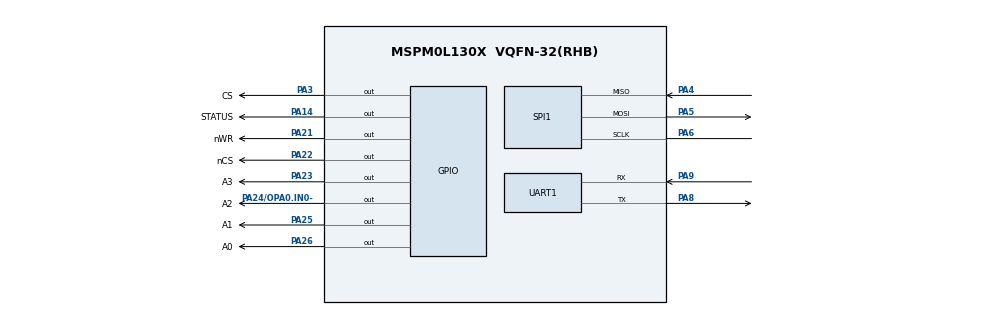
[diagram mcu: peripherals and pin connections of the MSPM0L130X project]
/**
 * @cliArgs --device "MSPM0L130X" --part "Default" --package "VQFN-32(RHB)" --product "mspm0_sdk@2.02.00.05"
 * @versions {"tool":"1.21.0+3721"}
 */

/**
 * Import the modules used in this configuration.
 */
const GPIO          = scripting.addModule("/ti/driverlib/GPIO", {}, false);
const GPIO1         = GPIO.addInstance();
const GPIO2         = GPIO.addInstance();
const GPIO3         = GPIO.addInstance();
const SPI           = scripting.addModule("/ti/driverlib/SPI", {}, false);
const SPI1          = SPI.addInstance();
const SYSCTL        = scripting.addModule("/ti/driverlib/SYSCTL");
const UART          = scripting.addModule("/ti/driverlib/UART", {}, false);
const UART1         = UART.addInstance();
const ProjectConfig = scripting.addModule("/ti/project_config/ProjectConfig");

/**
 * Write custom configuration values to the imported modules.
 */
GPIO1.port                          = "PORTA";
GPIO1.portSegment                   = "Lower";
GPIO1.$name                         = "GPIO_LED";
GPIO1.associatedPins[0].$name       = "STATUS";
GPIO1.associatedPins[0].pin.$assign = "PA14";

const Board = scripting.addModule("/ti/driverlib/Board", {}, false);

GPIO2.$name                         = "GPIO_MUX";
GPIO2.port                          = "PORTA";
GPIO2.portSegment                   = "Upper";
GPIO2.associatedPins.create(6);
GPIO2.associatedPins[0].$name       = "A0";
GPIO2.associatedPins[0].pin.$assign = "PA26";
GPIO2.associatedPins[1].$name       = "A1";
GPIO2.associatedPins[1].pin.$assign = "PA25";
GPIO2.associatedPins[2].$name       = "A2";
GPIO2.associatedPins[2].pin.$assign = "PA24/OPA0.IN0-";
GPIO2.associatedPins[3].$name       = "A3";
GPIO2.associatedPins[3].pin.$assign = "PA23";
GPIO2.associatedPins[4].$name       = "nCS";
GPIO2.associatedPins[4].pin.$assign = "PA22";
GPIO2.associatedPins[5].$name       = "nWR";
GPIO2.associatedPins[5].pin.$assign = "PA21";

GPIO3.$name                         = "GPIO_CS";
GPIO3.associatedPins[0].$name       = "CS";
GPIO3.associatedPins[0].pin.$assign = "PA3";

SPI1.$name                              = "SPI_AMP";
SPI1.targetBitRate                      = 100000;
SPI1.frameFormat                        = "MOTO3";
SPI1.peripheral.sclkPin.$assign         = "PA6";
SPI1.peripheral.mosiPin.$assign         = "PA5";
SPI1.peripheral.misoPin.$assign         = "PA4";
SPI1.sclkPinConfig.$name                = "ti_driverlib_gpio_GPIOPinGeneric0";
SPI1.sclkPinConfig.direction            = scripting.forceWrite("OUTPUT");
SPI1.sclkPinConfig.onlyInternalResistor = scripting.forceWrite(false);
SPI1.sclkPinConfig.passedPeripheralType = scripting.forceWrite("Digital");
SPI1.mosiPinConfig.$name                = "ti_driverlib_gpio_GPIOPinGeneric1";
SPI1.mosiPinConfig.direction            = scripting.forceWrite("OUTPUT");
SPI1.mosiPinConfig.hideOutputInversion  = scripting.forceWrite(false);
SPI1.mosiPinConfig.onlyInternalResistor = scripting.forceWrite(false);
SPI1.mosiPinConfig.passedPeripheralType = scripting.forceWrite("Digital");
SPI1.misoPinConfig.$name                = "ti_driverlib_gpio_GPIOPinGeneric2";
SPI1.misoPinConfig.onlyInternalResistor = scripting.forceWrite(false);
SPI1.misoPinConfig.passedPeripheralType = scripting.forceWrite("Digital");


UART1.$name                            = "UART_SERVICE";
UART1.targetBaudRate                   = 115200;
UART1.peripheral.rxPin.$assign         = "PA9";
UART1.peripheral.txPin.$assign         = "PA8";
UART1.txPinConfig.$name                = "ti_driverlib_gpio_GPIOPinGeneric3";
UART1.txPinConfig.direction            = scripting.forceWrite("OUTPUT");
UART1.txPinConfig.hideOutputInversion  = scripting.forceWrite(false);
UART1.txPinConfig.onlyInternalResistor = scripting.forceWrite(false);
UART1.txPinConfig.passedPeripheralType = scripting.forceWrite("Digital");
UART1.rxPinConfig.$name                = "ti_driverlib_gpio_GPIOPinGeneric4";
UART1.rxPinConfig.hideOutputInversion  = scripting.forceWrite(false);
UART1.rxPinConfig.onlyInternalResistor = scripting.forceWrite(false);
UART1.rxPinConfig.passedPeripheralType = scripting.forceWrite("Digital");

ProjectConfig.deviceSpin = "MSPM0L1306";

/**
 * Pinmux solution for unlocked pins/peripherals. This ensures that minor changes to the automatic solver in a future
 * version of the tool will not impact the pinmux you originally saw.  These lines can be completely deleted in order to
 * re-solve from scratch.
 */
Board.peripheral.$suggestSolution          = "DEBUGSS";
Board.peripheral.swclkPin.$suggestSolution = "PA20";
Board.peripheral.swdioPin.$suggestSolution = "PA19";
SPI1.peripheral.$suggestSolution           = "SPI0";
SYSCTL.peripheral.$suggestSolution         = "SYSCTL";
UART1.peripheral.$suggestSolution          = "UART0";
